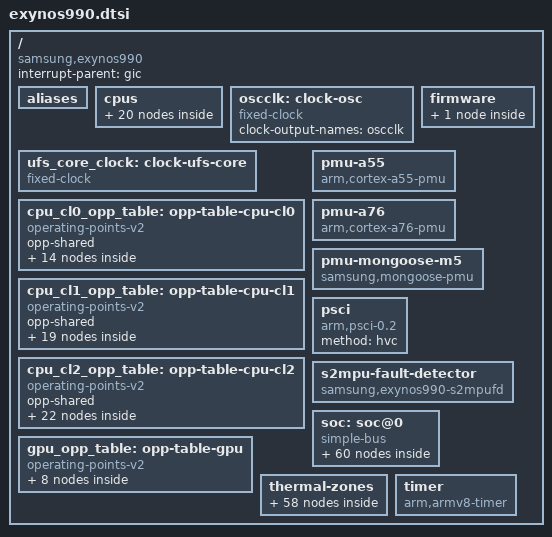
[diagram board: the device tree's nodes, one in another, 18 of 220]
// SPDX-License-Identifier: GPL-2.0 OR BSD-3-Clause
/*
 * Samsung Exynos 990 SoC device tree source
 *
 * Copyright (c) 2024, Igor Belwon <igor.belwon@mentallysanemainliners.org>
 */

#include <dt-bindings/clock/samsung,exynos990.h>
#include <dt-bindings/clock/samsung,exynos990-acpm.h>
#include <dt-bindings/interrupt-controller/arm-gic.h>
#include <dt-bindings/soc/samsung,exynos-usi.h>
#include <dt-bindings/thermal/thermal.h>

/ {
	compatible = "samsung,exynos990";
	#address-cells = <2>;
	#size-cells = <1>;

	interrupt-parent = <&gic>;

	aliases {
		pinctrl0 = &pinctrl_alive;
		pinctrl1 = &pinctrl_cmgp;
		pinctrl2 = &pinctrl_hsi1;
		pinctrl3 = &pinctrl_hsi2;
		pinctrl4 = &pinctrl_peric0;
		pinctrl5 = &pinctrl_peric1;
		pinctrl6 = &pinctrl_vts;
	};

	cpus {
		#address-cells = <1>;
		#size-cells = <0>;

		cpu-map {
			cluster0 {
				core0 {
					cpu = <&cpu0>;
				};

				core1 {
					cpu = <&cpu1>;
				};

				core2 {
					cpu = <&cpu2>;
				};

				core3 {
					cpu = <&cpu3>;
				};
			};

			cluster1 {
				core0 {
					cpu = <&cpu4>;
				};

				core1 {
					cpu = <&cpu5>;
				};
			};

			cluster2 {
				core0 {
					cpu = <&cpu6>;
				};

				core1 {
					cpu = <&cpu7>;
				};
			};
		};

		/*
		 * capacity-dmips-mhz and dynamic-power-coefficient: the vendor
		 * firmware's sched-energy-data (mips-per-mhz, power-coefficient)
		 * for ananke (A55), enyo (A76) and lion (M5).
		 */
		cpu0: cpu@0 {
			device_type = "cpu";
			compatible = "arm,cortex-a55";
			reg = <0x0>;
			enable-method = "psci";
			capacity-dmips-mhz = <270>;
			dynamic-power-coefficient = <120>;
			clocks = <&acpm_ipc EXYNOS990_CLK_ACPM_DVFS_CPUCL0>;
			operating-points-v2 = <&cpu_cl0_opp_table>;
			#cooling-cells = <2>;
		};

		cpu1: cpu@1 {
			device_type = "cpu";
			compatible = "arm,cortex-a55";
			reg = <0x1>;
			enable-method = "psci";
			capacity-dmips-mhz = <270>;
			dynamic-power-coefficient = <120>;
			clocks = <&acpm_ipc EXYNOS990_CLK_ACPM_DVFS_CPUCL0>;
			operating-points-v2 = <&cpu_cl0_opp_table>;
			#cooling-cells = <2>;
		};

		cpu2: cpu@2 {
			device_type = "cpu";
			compatible = "arm,cortex-a55";
			reg = <0x2>;
			enable-method = "psci";
			capacity-dmips-mhz = <270>;
			dynamic-power-coefficient = <120>;
			clocks = <&acpm_ipc EXYNOS990_CLK_ACPM_DVFS_CPUCL0>;
			operating-points-v2 = <&cpu_cl0_opp_table>;
			#cooling-cells = <2>;
		};

		cpu3: cpu@3 {
			device_type = "cpu";
			compatible = "arm,cortex-a55";
			reg = <0x3>;
			enable-method = "psci";
			capacity-dmips-mhz = <270>;
			dynamic-power-coefficient = <120>;
			clocks = <&acpm_ipc EXYNOS990_CLK_ACPM_DVFS_CPUCL0>;
			operating-points-v2 = <&cpu_cl0_opp_table>;
			#cooling-cells = <2>;
		};

		cpu4: cpu@100 {
			device_type = "cpu";
			compatible = "arm,cortex-a76";
			reg = <0x4>;
			enable-method = "psci";
			capacity-dmips-mhz = <673>;
			dynamic-power-coefficient = <370>;
			clocks = <&acpm_ipc EXYNOS990_CLK_ACPM_DVFS_CPUCL1>;
			operating-points-v2 = <&cpu_cl1_opp_table>;
			#cooling-cells = <2>;
		};

		cpu5: cpu@101 {
			device_type = "cpu";
			compatible = "arm,cortex-a76";
			reg = <0x5>;
			enable-method = "psci";
			capacity-dmips-mhz = <673>;
			dynamic-power-coefficient = <370>;
			clocks = <&acpm_ipc EXYNOS990_CLK_ACPM_DVFS_CPUCL1>;
			operating-points-v2 = <&cpu_cl1_opp_table>;
			#cooling-cells = <2>;
		};

		cpu6: cpu@200 {
			device_type = "cpu";
			compatible = "samsung,mongoose-m5";
			reg = <0x6>;
			enable-method = "psci";
			capacity-dmips-mhz = <806>;
			dynamic-power-coefficient = <860>;
			clocks = <&acpm_ipc EXYNOS990_CLK_ACPM_DVFS_CPUCL2>;
			operating-points-v2 = <&cpu_cl2_opp_table>;
			#cooling-cells = <2>;
		};

		cpu7: cpu@201 {
			device_type = "cpu";
			compatible = "samsung,mongoose-m5";
			reg = <0x7>;
			enable-method = "psci";
			capacity-dmips-mhz = <806>;
			dynamic-power-coefficient = <860>;
			clocks = <&acpm_ipc EXYNOS990_CLK_ACPM_DVFS_CPUCL2>;
			operating-points-v2 = <&cpu_cl2_opp_table>;
			#cooling-cells = <2>;
		};
	};

	oscclk: clock-osc {
		compatible = "fixed-clock";
		#clock-cells = <0>;
		clock-output-names = "oscclk";
	};

	/*
	 * UFS_EMBD from CMU_HSI1, which has no driver yet; S-Boot leaves it
	 * running at this rate (it boots from UFS).
	 */
	ufs_core_clock: clock-ufs-core {
		compatible = "fixed-clock";
		#clock-cells = <0>;
		clock-frequency = <166562500>;
		clock-output-names = "ufs_core";
	};

	firmware {
		/*
		 * The APM firmware: DVFS (it sets each domain's voltage with the rate), through the AP-to-APM mailbox and
		 * the channels it lists in its SRAM. Its FREQ_GET does not answer, so a rate is known only once set.
		 */
		acpm_ipc: power-management {
			compatible = "samsung,exynos990-acpm-ipc";
			#clock-cells = <1>;
			mboxes = <&ap2apm_mailbox>;
			shmem = <&apm_sram>;

			/*
			 * A rate is known only once set: the CPU clusters start at their top level (the M5s at the stock
			 * kernel's boot level), the GPU at its lowest, until cpufreq and devfreq take over.
			 */
			assigned-clocks = <&acpm_ipc EXYNOS990_CLK_ACPM_DVFS_CPUCL0>,
					  <&acpm_ipc EXYNOS990_CLK_ACPM_DVFS_CPUCL1>,
					  <&acpm_ipc EXYNOS990_CLK_ACPM_DVFS_CPUCL2>,
					  <&acpm_ipc EXYNOS990_CLK_ACPM_DVFS_G3D>;
			assigned-clock-rates = <2002000000>, <2504000000>, <2002000000>, <156000000>;
		};
	};

	/*
	 * The CPU clusters' levels from the bootloader's ECT, within the stock kernel's limits (the A76s at their
	 * advertised 2.5 GHz, not the 2.6 GHz the stock limit allows); ACPM picks each level's voltage.
	 */
	cpu_cl0_opp_table: opp-table-cpu-cl0 {
		compatible = "operating-points-v2";
		opp-shared;

		opp-442000000 {
			opp-hz = /bits/ 64 <442000000>;
		};

		opp-546000000 {
			opp-hz = /bits/ 64 <546000000>;
		};

		opp-650000000 {
			opp-hz = /bits/ 64 <650000000>;
		};

		opp-806000000 {
			opp-hz = /bits/ 64 <806000000>;
		};

		opp-949000000 {
			opp-hz = /bits/ 64 <949000000>;
		};

		opp-1053000000 {
			opp-hz = /bits/ 64 <1053000000>;
		};

		opp-1157000000 {
			opp-hz = /bits/ 64 <1157000000>;
		};

		opp-1300000000 {
			opp-hz = /bits/ 64 <1300000000>;
		};

		opp-1456000000 {
			opp-hz = /bits/ 64 <1456000000>;
		};

		opp-1586000000 {
			opp-hz = /bits/ 64 <1586000000>;
		};

		opp-1742000000 {
			opp-hz = /bits/ 64 <1742000000>;
		};

		opp-1846000000 {
			opp-hz = /bits/ 64 <1846000000>;
		};

		opp-1950000000 {
			opp-hz = /bits/ 64 <1950000000>;
		};

		opp-2002000000 {
			opp-hz = /bits/ 64 <2002000000>;
		};
	};

	/* Cortex-A76 */
	cpu_cl1_opp_table: opp-table-cpu-cl1 {
		compatible = "operating-points-v2";
		opp-shared;

		opp-507000000 {
			opp-hz = /bits/ 64 <507000000>;
		};

		opp-650000000 {
			opp-hz = /bits/ 64 <650000000>;
		};

		opp-754000000 {
			opp-hz = /bits/ 64 <754000000>;
		};

		opp-845000000 {
			opp-hz = /bits/ 64 <845000000>;
		};

		opp-962000000 {
			opp-hz = /bits/ 64 <962000000>;
		};

		opp-1066000000 {
			opp-hz = /bits/ 64 <1066000000>;
		};

		opp-1222000000 {
			opp-hz = /bits/ 64 <1222000000>;
		};

		opp-1404000000 {
			opp-hz = /bits/ 64 <1404000000>;
		};

		opp-1508000000 {
			opp-hz = /bits/ 64 <1508000000>;
		};

		opp-1586000000 {
			opp-hz = /bits/ 64 <1586000000>;
		};

		opp-1690000000 {
			opp-hz = /bits/ 64 <1690000000>;
		};

		opp-1794000000 {
			opp-hz = /bits/ 64 <1794000000>;
		};

		opp-1898000000 {
			opp-hz = /bits/ 64 <1898000000>;
		};

		opp-2002000000 {
			opp-hz = /bits/ 64 <2002000000>;
		};

		opp-2106000000 {
			opp-hz = /bits/ 64 <2106000000>;
		};

		opp-2210000000 {
			opp-hz = /bits/ 64 <2210000000>;
		};

		opp-2314000000 {
			opp-hz = /bits/ 64 <2314000000>;
		};

		opp-2400000000 {
			opp-hz = /bits/ 64 <2400000000>;
		};

		opp-2504000000 {
			opp-hz = /bits/ 64 <2504000000>;
		};
	};

	/* Mongoose M5 */
	cpu_cl2_opp_table: opp-table-cpu-cl2 {
		compatible = "operating-points-v2";
		opp-shared;

		opp-546000000 {
			opp-hz = /bits/ 64 <546000000>;
		};

		opp-650000000 {
			opp-hz = /bits/ 64 <650000000>;
		};

		opp-754000000 {
			opp-hz = /bits/ 64 <754000000>;
		};

		opp-858000000 {
			opp-hz = /bits/ 64 <858000000>;
		};

		opp-962000000 {
			opp-hz = /bits/ 64 <962000000>;
		};

		opp-1066000000 {
			opp-hz = /bits/ 64 <1066000000>;
		};

		opp-1170000000 {
			opp-hz = /bits/ 64 <1170000000>;
		};

		opp-1274000000 {
			opp-hz = /bits/ 64 <1274000000>;
		};

		opp-1378000000 {
			opp-hz = /bits/ 64 <1378000000>;
		};

		opp-1482000000 {
			opp-hz = /bits/ 64 <1482000000>;
		};

		opp-1586000000 {
			opp-hz = /bits/ 64 <1586000000>;
		};

		opp-1690000000 {
			opp-hz = /bits/ 64 <1690000000>;
		};

		opp-1794000000 {
			opp-hz = /bits/ 64 <1794000000>;
		};

		opp-1898000000 {
			opp-hz = /bits/ 64 <1898000000>;
		};

		opp-2002000000 {
			opp-hz = /bits/ 64 <2002000000>;
		};

		opp-2106000000 {
			opp-hz = /bits/ 64 <2106000000>;
		};

		opp-2210000000 {
			opp-hz = /bits/ 64 <2210000000>;
		};

		opp-2314000000 {
			opp-hz = /bits/ 64 <2314000000>;
		};

		opp-2418000000 {
			opp-hz = /bits/ 64 <2418000000>;
		};

		opp-2522000000 {
			opp-hz = /bits/ 64 <2522000000>;
		};

		opp-2626000000 {
			opp-hz = /bits/ 64 <2626000000>;
		};

		opp-2730000000 {
			opp-hz = /bits/ 64 <2730000000>;
		};
	};

	/* the stock kernel's eight G3D levels (455 MHz is its sustainable one); ACPM picks the voltage */
	gpu_opp_table: opp-table-gpu {
		compatible = "operating-points-v2";

		opp-156000000 {
			opp-hz = /bits/ 64 <156000000>;
		};

		opp-260000000 {
			opp-hz = /bits/ 64 <260000000>;
		};

		opp-377000000 {
			opp-hz = /bits/ 64 <377000000>;
		};

		opp-455000000 {
			opp-hz = /bits/ 64 <455000000>;
		};

		opp-507000000 {
			opp-hz = /bits/ 64 <507000000>;
		};

		opp-598000000 {
			opp-hz = /bits/ 64 <598000000>;
		};

		opp-702000000 {
			opp-hz = /bits/ 64 <702000000>;
		};

		opp-800000000 {
			opp-hz = /bits/ 64 <800000000>;
		};
	};

	pmu-a55 {
		compatible = "arm,cortex-a55-pmu";
		interrupts = <GIC_SPI 163 IRQ_TYPE_LEVEL_HIGH>,
			     <GIC_SPI 164 IRQ_TYPE_LEVEL_HIGH>,
			     <GIC_SPI 165 IRQ_TYPE_LEVEL_HIGH>,
			     <GIC_SPI 166 IRQ_TYPE_LEVEL_HIGH>;

		interrupt-affinity = <&cpu0>,
				     <&cpu1>,
				     <&cpu2>,
				     <&cpu3>;
	};

	pmu-a76 {
		compatible = "arm,cortex-a76-pmu";
		interrupts = <GIC_SPI 167 IRQ_TYPE_LEVEL_HIGH>,
			     <GIC_SPI 168 IRQ_TYPE_LEVEL_HIGH>;

		interrupt-affinity = <&cpu4>,
				     <&cpu5>;
	};

	pmu-mongoose-m5 {
		compatible = "samsung,mongoose-pmu";
		interrupts = <GIC_SPI 180 IRQ_TYPE_LEVEL_HIGH>,
			     <GIC_SPI 181 IRQ_TYPE_LEVEL_HIGH>;

		interrupt-affinity = <&cpu6>,
				     <&cpu7>;
	};

	psci {
		compatible = "arm,psci-0.2";
		method = "hvc";
	};

	/* Reports DMA that Samsung's EL2 blocked in an S2MPU */
	s2mpu-fault-detector {
		compatible = "samsung,exynos990-s2mpufd";
		interrupts = <GIC_SPI 319 IRQ_TYPE_LEVEL_HIGH>,
			     <GIC_SPI 326 IRQ_TYPE_LEVEL_HIGH>;
	};

	soc: soc@0 {
		compatible = "simple-bus";
		ranges = <0x0 0x0 0x0 0x20000000>;

		#address-cells = <1>;
		#size-cells = <1>;

		apm_sram: sram@2039000 {
			compatible = "mmio-sram";
			reg = <0x2039000 0x38000>;
			#address-cells = <1>;
			#size-cells = <1>;
			ranges = <0x0 0x2039000 0x38000>;
		};

		chipid@10000000 {
			compatible = "samsung,exynos990-chipid",
				     "samsung,exynos850-chipid";
			reg = <0x10000000 0x100>;
		};

		cmu_peris: clock-controller@10020000 {
			compatible = "samsung,exynos990-cmu-peris";
			reg = <0x10020000 0x8000>;
			#clock-cells = <1>;

			clocks = <&oscclk>,
				 <&cmu_top CLK_DOUT_CMU_PERIS_BUS>;
			clock-names = "oscclk", "bus";
		};

		timer@10040000 {
			compatible = "samsung,exynos990-mct",
				     "samsung,exynos4210-mct";
			reg = <0x10040000 0x800>;
			clocks = <&oscclk>, <&cmu_peris CLK_GOUT_PERIS_MCT_PCLK>;
			clock-names = "fin_pll", "mct";
			interrupts = <GIC_SPI 466 IRQ_TYPE_LEVEL_HIGH>,
				     <GIC_SPI 467 IRQ_TYPE_LEVEL_HIGH>,
				     <GIC_SPI 468 IRQ_TYPE_LEVEL_HIGH>,
				     <GIC_SPI 469 IRQ_TYPE_LEVEL_HIGH>,
				     <GIC_SPI 470 IRQ_TYPE_LEVEL_HIGH>,
				     <GIC_SPI 471 IRQ_TYPE_LEVEL_HIGH>,
				     <GIC_SPI 472 IRQ_TYPE_LEVEL_HIGH>,
				     <GIC_SPI 473 IRQ_TYPE_LEVEL_HIGH>,
				     <GIC_SPI 474 IRQ_TYPE_LEVEL_HIGH>,
				     <GIC_SPI 475 IRQ_TYPE_LEVEL_HIGH>,
				     <GIC_SPI 476 IRQ_TYPE_LEVEL_HIGH>,
				     <GIC_SPI 477 IRQ_TYPE_LEVEL_HIGH>;
		};

		watchdog_cl0: watchdog@10050000 {
			compatible = "samsung,exynos990-wdt";
			reg = <0x10050000 0x100>;
			interrupts = <GIC_SPI 464 IRQ_TYPE_LEVEL_HIGH>;
			clocks = <&cmu_peris CLK_GOUT_PERIS_WDT_CLUSTER0_PCLK>,
				 <&oscclk>;
			clock-names = "watchdog",
				      "watchdog_src";
			samsung,syscon-phandle = <&pmu_system_controller>;
			samsung,cluster-index = <0>;
		};

		watchdog_cl2: watchdog@10060000 {
			compatible = "samsung,exynos990-wdt";
			reg = <0x10060000 0x100>;
			interrupts = <GIC_SPI 465 IRQ_TYPE_LEVEL_HIGH>;
			clocks = <&cmu_peris CLK_GOUT_PERIS_WDT_CLUSTER2_PCLK>,
				 <&oscclk>;
			clock-names = "watchdog",
				      "watchdog_src";
			samsung,syscon-phandle = <&pmu_system_controller>;
			samsung,cluster-index = <2>;
		};

		/* the CPU clusters' TMU, then the GPU's, ISP's and NPU's; the APM firmware runs both */
		tmu: thermal-sensor@10090000 {
			compatible = "samsung,exynos990-tmu";
			reg = <0x10090000 0x800>,
			      <0x100a0000 0x800>;
			interrupts = <GIC_SPI 478 IRQ_TYPE_LEVEL_HIGH>,
				     <GIC_SPI 479 IRQ_TYPE_LEVEL_HIGH>;
			samsung,acpm-ipc = <&acpm_ipc>;
			#thermal-sensor-cells = <1>;
		};

		gic: interrupt-controller@10101000 {
			compatible = "arm,gic-400";
			reg = <0x10101000 0x1000>,
			      <0x10102000 0x1000>,
			      <0x10104000 0x2000>,
			      <0x10106000 0x2000>;
			#interrupt-cells = <3>;
			interrupt-controller;
			interrupts = <GIC_PPI 9 (GIC_CPU_MASK_SIMPLE(8) |
						 IRQ_TYPE_LEVEL_HIGH)>;
			#address-cells = <0>;
			#size-cells = <1>;
		};

		cmu_peric0: clock-controller@10400000 {
			compatible = "samsung,exynos990-cmu-peric0";
			reg = <0x10400000 0x8000>;
			#clock-cells = <1>;

			clocks = <&oscclk>,
				 <&cmu_top CLK_DOUT_CMU_PERIC0_BUS>,
				 <&cmu_top CLK_DOUT_CMU_PERIC0_IP>;
			clock-names = "oscclk", "bus", "ip";
		};

		sysreg_peric0: syscon@10420000 {
			compatible = "samsung,exynos990-peric0-sysreg", "syscon";
			reg = <0x10420000 0x10000>;
			clocks = <&cmu_peric0 CLK_GOUT_PERIC0_SYSREG_PCLK>;
		};

		/* PWM timers; stock counts them at OSCCLK ("pwm-clock" = fin_pll) */
		pwm: pwm@106f0000 {
			compatible = "samsung,s3c6400-pwm";
			reg = <0x106f0000 0x1000>;
			clocks = <&oscclk>;
			clock-names = "timers";
			#pwm-cells = <3>;
			status = "disabled";
		};

		pinctrl_peric0: pinctrl@10430000 {
			compatible = "samsung,exynos990-pinctrl";
			reg = <0x10430000 0x1000>;
			interrupts = <GIC_SPI 392 IRQ_TYPE_LEVEL_HIGH>;
		};

		/*
		 * USI03's dedicated I2C channel (vendor hsi2c7). Its CMU ports
		 * sit right after USI03's own (IPCLK/PCLK 11): 12. No protocol
		 * selector in the sysreg, only USI_CON/USI_OPTION at +0xc0.
		 */
		usi_i2c_peric0_3: usi@105c00c0 {
			compatible = "samsung,exynos850-usi";
			reg = <0x105c00c0 0x20>;
			ranges;
			#address-cells = <1>;
			#size-cells = <1>;
			clocks = <&cmu_peric0 CLK_GOUT_PERIC0_TOP0_PCLK_12>,
				 <&cmu_peric0 CLK_GOUT_PERIC0_TOP0_IPCLK_12>;
			clock-names = "pclk", "ipclk";
			samsung,mode = <USI_MODE_I2C>;
			status = "disabled";

			hsi2c_7: i2c@105c0000 {
				compatible = "samsung,exynosautov9-hsi2c";
				reg = <0x105c0000 0xc0>;
				interrupts = <GIC_SPI 404 IRQ_TYPE_LEVEL_HIGH>;
				clocks = <&cmu_peric0 CLK_GOUT_PERIC0_TOP0_IPCLK_12>,
					 <&cmu_peric0 CLK_GOUT_PERIC0_TOP0_PCLK_12>;
				clock-names = "hsi2c", "hsi2c_pclk";
				pinctrl-names = "default";
				pinctrl-0 = <&hsi2c7_bus>;
				#address-cells = <1>;
				#size-cells = <0>;
				status = "disabled";
			};
		};

		/* PERIC0 USI14 ("spi14" downstream, mode word usi_14 = sysreg +0x1044) */
		usi_spi14: usi@106500c0 {
			compatible = "samsung,exynos850-usi";
			reg = <0x106500c0 0x20>;
			ranges;
			#address-cells = <1>;
			#size-cells = <1>;
			clocks = <&cmu_peric0 CLK_GOUT_PERIC0_TOP1_PCLK_5>,
				 <&cmu_peric0 CLK_GOUT_PERIC0_TOP1_IPCLK_5>;
			clock-names = "pclk", "ipclk";
			samsung,sysreg = <&sysreg_peric0 0x1044>;
			samsung,mode = <USI_MODE_SPI>;
			status = "disabled";

			spi_14: spi@10650000 {
				compatible = "samsung,exynos850-spi";
				reg = <0x10650000 0x30>;
				interrupts = <GIC_SPI 413 IRQ_TYPE_LEVEL_HIGH>;
				clocks = <&cmu_peric0 CLK_GOUT_PERIC0_TOP1_PCLK_5>,
					 <&cmu_peric0 CLK_GOUT_PERIC0_TOP1_IPCLK_5>;
				clock-names = "spi", "spi_busclk0";
				pinctrl-names = "default";
				pinctrl-0 = <&spi14_bus &spi14_cs_func>;
				#address-cells = <1>;
				#size-cells = <0>;
				status = "disabled";
			};
		};

		/*
		 * USI15's dedicated I2C channel (vendor hsi2c31, the speaker amps).
		 * Its ports are TOP1 IPCLK/PCLK 8: the last of the four I2C halves
		 * (0, 4, 6, 8) that hang off DIV_CLK_PERIC0_USI_I2C.
		 */
		usi_i2c_peric0_15: usi@106800c0 {
			compatible = "samsung,exynos850-usi";
			reg = <0x106800c0 0x20>;
			ranges;
			#address-cells = <1>;
			#size-cells = <1>;
			clocks = <&cmu_peric0 CLK_GOUT_PERIC0_TOP1_PCLK_8>,
				 <&cmu_peric0 CLK_GOUT_PERIC0_TOP1_IPCLK_8>;
			clock-names = "pclk", "ipclk";
			samsung,mode = <USI_MODE_I2C>;
			status = "disabled";

			hsi2c_31: i2c@10680000 {
				compatible = "samsung,exynosautov9-hsi2c";
				reg = <0x10680000 0xc0>;
				interrupts = <GIC_SPI 414 IRQ_TYPE_LEVEL_HIGH>;
				clocks = <&cmu_peric0 CLK_GOUT_PERIC0_TOP1_IPCLK_8>,
					 <&cmu_peric0 CLK_GOUT_PERIC0_TOP1_PCLK_8>;
				clock-names = "hsi2c", "hsi2c_pclk";
				pinctrl-names = "default";
				pinctrl-0 = <&hsi2c31_bus>;
				#address-cells = <1>;
				#size-cells = <0>;
				status = "disabled";
			};
		};

		cmu_peric1: clock-controller@10700000 {
			compatible = "samsung,exynos990-cmu-peric1";
			reg = <0x10700000 0x8000>;
			#clock-cells = <1>;

			clocks = <&oscclk>,
				 <&cmu_top CLK_DOUT_CMU_PERIC1_BUS>,
				 <&cmu_top CLK_DOUT_CMU_PERIC1_IP>;
			clock-names = "oscclk", "bus", "ip";
		};

		sysreg_peric1: syscon@10720000 {
			compatible = "samsung,exynos990-peric1-sysreg", "syscon";
			reg = <0x10720000 0x10000>;
			clocks = <&cmu_peric1 CLK_GOUT_PERIC1_SYSREG_PCLK>;
		};

		pinctrl_peric1: pinctrl@10730000 {
			compatible = "samsung,exynos990-pinctrl";
			reg = <0x10730000 0x1000>;
			interrupts = <GIC_SPI 417 IRQ_TYPE_LEVEL_HIGH>;
		};

		/* UART1 ("UART_BT" downstream, USI47 in the sysreg): ports 4 */
		usi_uart_bt: usi@108400c0 {
			compatible = "samsung,exynos850-usi";
			reg = <0x108400c0 0x20>;
			ranges;
			#address-cells = <1>;
			#size-cells = <1>;
			clocks = <&cmu_peric1 CLK_GOUT_PERIC1_TOP0_PCLK_4>,
				 <&cmu_peric1 CLK_GOUT_PERIC1_TOP0_IPCLK_4>;
			clock-names = "pclk", "ipclk";
			samsung,sysreg = <&sysreg_peric1 0x1000>;
			samsung,mode = <USI_MODE_UART>;
			samsung,clkreq-on;
			status = "disabled";

			serial_1: serial@10840000 {
				compatible = "samsung,exynos8895-uart";
				reg = <0x10840000 0xc0>;
				interrupts = <GIC_SPI 416 IRQ_TYPE_LEVEL_HIGH>;
				clocks = <&cmu_peric1 CLK_GOUT_PERIC1_TOP0_PCLK_4>,
					 <&cmu_peric1 CLK_GOUT_PERIC1_TOP0_IPCLK_4>;
				clock-names = "uart", "clk_uart_baud0";
				samsung,uart-fifosize = <256>;
				pinctrl-names = "default";
				pinctrl-0 = <&uart1_bus_single>;
				status = "disabled";
			};
		};

		/* USI07's dedicated I2C channel (vendor hsi2c15): ports 13 */
		usi_i2c_peric1_7: usi@108d00c0 {
			compatible = "samsung,exynos850-usi";
			reg = <0x108d00c0 0x20>;
			ranges;
			#address-cells = <1>;
			#size-cells = <1>;
			clocks = <&cmu_peric1 CLK_GOUT_PERIC1_TOP0_PCLK_13>,
				 <&cmu_peric1 CLK_GOUT_PERIC1_TOP0_IPCLK_13>;
			clock-names = "pclk", "ipclk";
			samsung,mode = <USI_MODE_I2C>;
			status = "disabled";

			hsi2c_15: i2c@108d0000 {
				compatible = "samsung,exynosautov9-hsi2c";
				reg = <0x108d0000 0xc0>;
				interrupts = <GIC_SPI 420 IRQ_TYPE_LEVEL_HIGH>;
				clocks = <&cmu_peric1 CLK_GOUT_PERIC1_TOP0_IPCLK_13>,
					 <&cmu_peric1 CLK_GOUT_PERIC1_TOP0_PCLK_13>;
				clock-names = "hsi2c", "hsi2c_pclk";
				pinctrl-names = "default";
				pinctrl-0 = <&hsi2c15_bus>;
				#address-cells = <1>;
				#size-cells = <0>;
				status = "disabled";
			};
		};

		/* PERIC1 USI16 ("spi16" downstream, mode word usi_16 = sysreg +0x1048) */
		usi_spi16: usi@109600c0 {
			compatible = "samsung,exynos850-usi";
			reg = <0x109600c0 0x20>;
			ranges;
			#address-cells = <1>;
			#size-cells = <1>;
			clocks = <&cmu_peric1 CLK_GOUT_PERIC1_TOP1_PCLK_6>,
				 <&cmu_peric1 CLK_GOUT_PERIC1_TOP1_IPCLK_6>;
			clock-names = "pclk", "ipclk";
			samsung,sysreg = <&sysreg_peric1 0x1048>;
			samsung,mode = <USI_MODE_SPI>;
			status = "disabled";

			spi_16: spi@10960000 {
				compatible = "samsung,exynos850-spi";
				reg = <0x10960000 0x30>;
				interrupts = <GIC_SPI 434 IRQ_TYPE_LEVEL_HIGH>;
				clocks = <&cmu_peric1 CLK_GOUT_PERIC1_TOP1_PCLK_6>,
					 <&cmu_peric1 CLK_GOUT_PERIC1_TOP1_IPCLK_6>;
				clock-names = "spi", "spi_busclk0";
				pinctrl-names = "default";
				pinctrl-0 = <&spi16_bus &spi16_cs_func>;
				#address-cells = <1>;
				#size-cells = <0>;
				status = "disabled";
			};
		};

		/*
		 * USI12's dedicated I2C channel (vendor hsi2c25, the NFC): ports
		 * TOP1 13, the I2C half next to USI12's own 12.
		 */
		usi_i2c_peric1_12: usi@109d00c0 {
			compatible = "samsung,exynos850-usi";
			reg = <0x109d00c0 0x20>;
			ranges;
			#address-cells = <1>;
			#size-cells = <1>;
			clocks = <&cmu_peric1 CLK_GOUT_PERIC1_TOP1_PCLK_13>,
				 <&cmu_peric1 CLK_GOUT_PERIC1_TOP1_IPCLK_13>;
			clock-names = "pclk", "ipclk";
			samsung,mode = <USI_MODE_I2C>;
			status = "disabled";

			hsi2c_25: i2c@109d0000 {
				compatible = "samsung,exynosautov9-hsi2c";
				reg = <0x109d0000 0xc0>;
				interrupts = <GIC_SPI 430 IRQ_TYPE_LEVEL_HIGH>;
				clocks = <&cmu_peric1 CLK_GOUT_PERIC1_TOP1_IPCLK_13>,
					 <&cmu_peric1 CLK_GOUT_PERIC1_TOP1_PCLK_13>;
				clock-names = "hsi2c", "hsi2c_pclk";
				pinctrl-names = "default";
				pinctrl-0 = <&hsi2c25_bus>;
				#address-cells = <1>;
				#size-cells = <0>;
				status = "disabled";
			};
		};

		cmu_hsi0: clock-controller@10a00000 {
			compatible = "samsung,exynos990-cmu-hsi0";
			reg = <0x10a00000 0x8000>;
			#clock-cells = <1>;

			clocks = <&oscclk>,
				 <&cmu_top CLK_DOUT_CMU_HSI0_BUS>,
				 <&cmu_top CLK_DOUT_CMU_HSI0_USB31DRD>,
				 <&cmu_top CLK_DOUT_CMU_HSI0_USBDP_DEBUG>,
				 <&cmu_top CLK_DOUT_CMU_HSI0_DPGTC>;
			clock-names = "oscclk",
				      "bus",
				      "usb31drd",
				      "usbdp_debug",
				      "dpgtc";
		};

		usbdrd_phy: phy@10c00000 {
			compatible = "samsung,exynos990-usbdrd-phy";
			reg = <0x10c00000 0x100>;
			clocks = <&cmu_hsi0 CLK_GOUT_HSI0_USB31DRD_ACLK_PHYCTRL>,
				 <&oscclk>;
			clock-names = "phy", "ref";
			samsung,pmu-syscon = <&pmu_system_controller>;
			#phy-cells = <1>;
			status = "disabled";
		};

		usbdrd: usb@10e00000 {
			compatible = "samsung,exynos990-dwusb3",
				     "samsung,exynos850-dwusb3";
			ranges = <0x0 0x10e00000 0x10000>;
			clocks = <&cmu_hsi0 CLK_GOUT_HSI0_USB31DRD_BUS_CLK_EARLY>,
				 <&cmu_hsi0 CLK_GOUT_HSI0_USB31DRD_USB31DRD_REF_CLK_40>;
			clock-names = "bus_early", "ref";
			#address-cells = <1>;
			#size-cells = <1>;
			status = "disabled";

			usbdrd_dwc3: usb@0 {
				compatible = "snps,dwc3";
				reg = <0x0 0x10000>;
				interrupts = <GIC_SPI 310 IRQ_TYPE_LEVEL_HIGH>;
				phys = <&usbdrd_phy 0>;
				phy-names = "usb2-phy";
			};
		};

		sysreg_hsi1: syscon@13020000 {
			compatible = "samsung,exynos990-hsi1-sysreg", "syscon";
			reg = <0x13020000 0x1000>;
		};

		pinctrl_hsi1: pinctrl@13040000 {
			compatible = "samsung,exynos990-pinctrl";
			reg = <0x13040000 0x1000>;
			interrupts = <GIC_SPI 312 IRQ_TYPE_LEVEL_HIGH>;
		};

		ufs_0: ufs@13100000 {
			compatible = "samsung,exynos990-ufs";
			reg = <0x13100000 0x200>,
			      <0x13101100 0x200>,
			      <0x13180000 0x8000>,
			      <0x132a0000 0x100>;
			reg-names = "hci", "vs_hci", "unipro", "ufsp";
			interrupts = <GIC_SPI 321 IRQ_TYPE_LEVEL_HIGH>;
			clocks = <&ufs_core_clock>, <&ufs_core_clock>;
			clock-names = "core_clk", "sclk_unipro_main";
			freq-table-hz = <0 0>, <0 0>;
			pinctrl-names = "default";
			pinctrl-0 = <&ufs_rst_n &ufs_refclk_out>;
			phys = <&ufs_0_phy>;
			phy-names = "ufs-phy";
			samsung,sysreg = <&sysreg_hsi1 0x700>;
			/* the stock DT's: descriptors and buffers snooped (io coherency bits set by the driver) */
			dma-coherent;
			status = "disabled";
		};

		ufs_0_phy: phy@13104000 {
			compatible = "samsung,exynos990-ufs-phy";
			reg = <0x13104000 0x3000>;
			reg-names = "phy-pma";
			clocks = <&oscclk>;
			clock-names = "ref_clk";
			samsung,pmu-syscon = <&pmu_system_controller>;
			#phy-cells = <0>;
			status = "disabled";
		};

		/* GEN2 x1 root complex, channel 0: the Wi-Fi's on the S20 FE (stock pcie@133b0000) */
		pcie_0: pcie@133b0000 {
			compatible = "samsung,exynos990-pcie";
			reg = <0x133f0000 0x1000>,
			      <0x133b0000 0x1000>,
			      <0x133e0000 0x1000>,
			      <0x133d0000 0x200>,
			      <0x11ffe000 0x2000>;
			reg-names = "dbi", "elbi", "phy", "pcs", "config";
			#address-cells = <3>;
			#size-cells = <2>;
			device_type = "pci";
			ranges = <0x82000000 0 0x11000000 0x11000000 0 0x00ff0000>;
			bus-range = <0x00 0xff>;
			num-lanes = <1>;
			max-link-speed = <2>;
			interrupts = <GIC_SPI 314 IRQ_TYPE_LEVEL_HIGH>;
			#interrupt-cells = <1>;
			interrupt-map-mask = <0 0 0 0>;
			interrupt-map = <0 0 0 0 &gic GIC_SPI 314 IRQ_TYPE_LEVEL_HIGH>;
			pinctrl-names = "default";
			pinctrl-0 = <&pcie0_clkreq &pcie0_perst>;
			samsung,pmu-syscon = <&pmu_system_controller>;
			samsung,sysreg = <&sysreg_hsi1>;
			status = "disabled";
		};

		/*
		 * GEN4 x2 root complex, channel 1 (HSI2; stock pcie@13d20000): the
		 * S5123 modem's on the S20 FE. The DBI is one 0x301000 window
		 * downstream; DBI2 (+1 MiB) and the iATU (+3 MiB) are given apart.
		 */
		pcie_1: pcie@13d20000 {
			compatible = "samsung,exynos990-pcie-gen4";
			reg = <0x13800000 0x1000>,
			      <0x13900000 0x1000>,
			      <0x13b00000 0x1000>,
			      <0x13d20000 0x2000>,
			      <0x13d50000 0x2000>,
			      <0x13d40000 0x1000>,
			      <0x14ffe000 0x2000>;
			reg-names = "dbi", "dbi2", "atu", "elbi", "phy", "pcs", "config";
			#address-cells = <3>;
			#size-cells = <2>;
			device_type = "pci";
			ranges = <0x82000000 0 0x14d00000 0x14000000 0 0x00ff0000>;
			bus-range = <0x00 0xff>;
			num-lanes = <2>;
			max-link-speed = <3>;
			interrupts = <GIC_SPI 323 IRQ_TYPE_LEVEL_HIGH>;
			#interrupt-cells = <1>;
			interrupt-map-mask = <0 0 0 0>;
			interrupt-map = <0 0 0 0 &gic GIC_SPI 323 IRQ_TYPE_LEVEL_HIGH>;
			clocks = <&cmu_top CLK_GOUT_CMU_HSI2_BUS>,
				 <&cmu_top CLK_GOUT_CMU_HSI2_PCIE>;
			clock-names = "bus", "pcie";
			pinctrl-names = "default";
			pinctrl-0 = <&pcie2_clkreq &pcie2_perst>;
			samsung,pmu-syscon = <&pmu_system_controller 0x720>;
			status = "disabled";
		};

		pinctrl_hsi2: pinctrl@13c30000 {
			compatible = "samsung,exynos990-pinctrl";
			reg = <0x13c30000 0x1000>;
			interrupts = <GIC_SPI 322 IRQ_TYPE_LEVEL_HIGH>;
		};

		pinctrl_vts: pinctrl@15580000 {
			compatible = "samsung,exynos990-pinctrl";
			reg = <0x15580000 0x1000>;
		};

		pinctrl_alive: pinctrl@15850000 {
			compatible = "samsung,exynos990-pinctrl";
			reg = <0x15850000 0x1000>;

			wakeup-interrupt-controller {
				compatible = "samsung,exynos990-wakeup-eint",
					     "samsung,exynos850-wakeup-eint",
					     "samsung,exynos7-wakeup-eint";
			};
		};

		pmu_system_controller: system-controller@15860000 {
			compatible = "samsung,exynos990-pmu",
				     "samsung,exynos7-pmu", "syscon";
			reg = <0x15860000 0x10000>;
			google,pmu-intr-gen-syscon = <&pmu_intr_gen>;
			/* CLKOUT1 (exynos-clkout): select 0 is the TCXO */
			#clock-cells = <1>;
			clocks = <&oscclk>;
			clock-names = "clkout0";
			assigned-clocks = <&pmu_system_controller 0>;
			assigned-clock-parents = <&oscclk>;

			reboot: syscon-reboot {
				compatible = "syscon-reboot";
				regmap = <&pmu_system_controller>;
				offset = <0x3a00>; /* SWRESET */
				mask = <0x2>; /* SWRESET_TRIGGER */
				value = <0x2>;
			};
		};

		pd_csis: power-domain@15861d80 {
			compatible = "samsung,exynos990-pd";
			reg = <0x15861d80 0x20>;
			#power-domain-cells = <0>;
			label = "CSIS";
			/* "need_smc" of the vendor DT's pd-csis */
			samsung,tzpc-base = <0x17010204>;
		};

		pd_g3d: power-domain@15862200 {
			compatible = "samsung,exynos990-pd";
			reg = <0x15862200 0x20>;
			#power-domain-cells = <0>;
			label = "G3D";
			/* the secure monitor restores the G3D's TZPC after a power-up ("need_smc" in the vendor DT) */
			samsung,tzpc-base = <0x18410204>;
		};

		pmu_intr_gen: syscon@15870000 {
			compatible = "samsung,exynos990-pmu-intr-gen", "syscon";
			reg = <0x15870000 0x10000>;
		};

		ap2apm_mailbox: mailbox@15900000 {
			compatible = "samsung,exynos990-mbox";
			reg = <0x15900000 0x1000>;
			interrupts = <GIC_SPI 41 IRQ_TYPE_LEVEL_HIGH>;
			#mbox-cells = <0>;
		};

		pinctrl_cmgp: pinctrl@15c30000 {
			compatible = "samsung,exynos990-pinctrl";
			reg = <0x15c30000 0x1000>;

			/* every gpm bank is a wakeup bank with its own SPI */
			wakeup-interrupt-controller {
				compatible = "samsung,exynos990-wakeup-eint",
					     "samsung,exynos850-wakeup-eint",
					     "samsung,exynos7-wakeup-eint";
			};
		};

		adc: adc@15c40000 {
			compatible = "samsung,exynos990-adc";
			reg = <0x15c40000 0x100>;
			interrupts = <GIC_SPI 83 IRQ_TYPE_LEVEL_HIGH>;
			/*
			 * CMU_CMGP has no clock driver yet; the ADC's gates there
			 * are on from boot and the oscillator stands in for them.
			 */
			clocks = <&oscclk>;
			clock-names = "adc";
			#io-channel-cells = <1>;
			status = "disabled";
		};

		/*
		 * CMU_CSIS, in pd_csis with the camera receivers. Its USER mux
		 * takes CMU_TOP's CSIS bus clock, as stock sets it.
		 */
		cmu_csis: clock-controller@17000000 {
			compatible = "samsung,exynos990-cmu-csis";
			reg = <0x17000000 0x8000>;
			#clock-cells = <1>;

			clock-names = "oscclk", "bus";
			clocks = <&oscclk>,
				 <&cmu_top CLK_DOUT_CMU_CSIS_BUS>;
			assigned-clocks = <&cmu_csis CLK_MOUT_CSIS_BUS_USER>;
			assigned-clock-parents = <&cmu_top CLK_DOUT_CMU_CSIS_BUS>;
			power-domains = <&pd_csis>;
		};

		/*
		 * CSIS4, a CSIS v5.3 MIPI CSI-2 link on the D/C-combo PHY
		 * csi4 (used in D-PHY mode), written to memory by WDMA0 (its
		 * VC0 and common registers). The PHYs' shared bias, the WDMAs'
		 * common top, SYSREG_CSIS (the PHY resets and the WDMA input
		 * muxes) and the PMU's MIPI PHY isolation word are shared with
		 * the other links. The SysMMUs are not used: the WDMA writes
		 * 32-bit physical addresses. bts-d0 and bts-d1 are the bus
		 * traffic shapers on CSIS's two AXI ports, in the always-on bus
		 * block.
		 */
		csis4: csis@17070000 {
			compatible = "samsung,exynos990-csis";
			reg = <0x17070000 0x1000>,
			      <0x170c1000 0x500>,
			      <0x170d2300 0x500>,
			      <0x170d1000 0x10>,
			      <0x170c0000 0x100>,
			      <0x17020000 0x1000>,
			      <0x15860730 0x4>,
			      <0x1b000000 0x100>,
			      <0x1b010000 0x100>;
			reg-names = "csis", "wdma", "phy", "phy-bias", "dma-top",
				    "sysreg", "pmu-iso", "bts-d0", "bts-d1";
			interrupts = <GIC_SPI 186 IRQ_TYPE_LEVEL_HIGH>,
				     <GIC_SPI 188 IRQ_TYPE_LEVEL_HIGH>;
			interrupt-names = "csis", "dma";
			clocks = <&cmu_csis CLK_GOUT_CSIS_PDP_CSIS4_ACLK>,
				 <&cmu_csis CLK_GOUT_CSIS_PDP_CSIS_DMA_ACLK>,
				 <&cmu_csis CLK_GOUT_CSIS_PDP_PDP_TOP_ACLK>,
				 <&cmu_csis CLK_GOUT_CSIS_QE_CSIS_DMA0_ACLK>,
				 <&cmu_csis CLK_GOUT_CSIS_XIU_D0_CSIS_ACLK>,
				 <&cmu_csis CLK_GOUT_CSIS_XIU_D1_CSIS_ACLK>,
				 <&cmu_csis CLK_GOUT_CSIS_SYSMMU_D0_CSIS_CLK_S1>,
				 <&cmu_csis CLK_GOUT_CSIS_SYSMMU_D1_CSIS_CLK_S1>,
				 <&cmu_csis CLK_GOUT_CSIS_LHS_AXI_D0_CSIS_CLK>,
				 <&cmu_csis CLK_GOUT_CSIS_LHS_AXI_D1_CSIS_CLK>,
				 <&acpm_ipc EXYNOS990_CLK_ACPM_DVFS_CAM>,
				 <&cmu_top CLK_MOUT_CMU_CSIS_BUS>;
			/*
			 * cam-dvfs: the APM firmware's CAM domain, which sets the CSIS
			 * bus (CMU_TOP) with CAM's voltage; bus: that clock's mux, read
			 * back after a CAM request.
			 */
			clock-names = "csis", "dma", "pdp-top", "qe-dma0",
				      "xiu-d0", "xiu-d1", "sysmmu-d0", "sysmmu-d1",
				      "axi-d0", "axi-d1", "cam-dvfs", "bus";
			power-domains = <&pd_csis>;
			samsung,csis-id = <4>;
			samsung,wdma-id = <0>;
			samsung,phy-reset-bit = <2>;
			samsung,dc-combo-phy;
			status = "disabled";
		};

		gpu: gpu@18500000 {
			compatible = "samsung,exynos990-mali", "arm,mali-valhall-jm";
			reg = <0x18500000 0x5000>;
			interrupts = <GIC_SPI 301 IRQ_TYPE_LEVEL_HIGH>,
				     <GIC_SPI 302 IRQ_TYPE_LEVEL_HIGH>,
				     <GIC_SPI 300 IRQ_TYPE_LEVEL_HIGH>;
			interrupt-names = "job", "mmu", "gpu";
			clocks = <&acpm_ipc EXYNOS990_CLK_ACPM_DVFS_G3D>;
			power-domains = <&pd_g3d>;
			operating-points-v2 = <&gpu_opp_table>;
			#cooling-cells = <2>;
			status = "disabled";
		};

		/*
		 * DECON0 with the IDMA channel 0 and DSIM0 the bootloader drives the
		 * built-in panel through. FRAME_START is the first of DECON0's
		 * interrupts (then FRAME_DONE, EXTRA).
		 */
		/*
		 * ABOX audio block (v3.0.1), run without its firmware: only the
		 * SFR and CMU_AUD are used; its DMAs go through SysMMU_AUD.
		 */
		abox: audio-controller@18c50000 {
			compatible = "samsung,exynos990-abox";
			/* SRAM, timer and ABOX's own GIC-400: for the calliope firmware */
			reg = <0x18c50000 0x10000>, <0x18c00000 0x3000>,
			      <0x18d00000 0x78c00>, <0x18ce0000 0x1000>,
			      <0x18cf1000 0x1000>, <0x18cf2000 0x1004>;
			reg-names = "sfr", "cmu", "sram", "timer", "gicd", "gicc";
			interrupts = <GIC_SPI 53 IRQ_TYPE_EDGE_RISING>;
			interrupt-names = "gic";
			samsung,pmu-syscon = <&pmu_system_controller>;
			iommus = <&sysmmu_aud>;
			#sound-dai-cells = <1>;
			status = "disabled";
		};

		/*
		 * VTS serial LIF: the PDM microphones' DMIC_AUD decimators and
		 * the DSP_A link that clocks them into ABOX UAIF6. "vts" is the
		 * VTS SFR's DMIC_IF/pad-select words, "cmu" CMU_VTS's dividers.
		 */
		vts_slif: audio-codec@15340000 {
			compatible = "samsung,exynos990-vts-slif";
			reg = <0x15340000 0x400>, <0x15350000 0x20>,
			      <0x15360000 0x20>, <0x15370000 0x20>,
			      <0x15511000 0x20>, <0x15501800 0x20>;
			reg-names = "sfr", "dmic0", "dmic1", "dmic2", "vts", "cmu";
			#sound-dai-cells = <0>;
			status = "disabled";
		};

		/* SysMMU v7.4 (VM capable) in front of the ABOX DMAs */
		sysmmu_aud: iommu@18e50000 {
			compatible = "samsung,exynos-sysmmu";
			reg = <0x18e50000 0x9000>;
			interrupts = <GIC_SPI 55 IRQ_TYPE_LEVEL_HIGH>;
			/* its gate (CMU_AUD) is left on; no CMU_AUD clock driver */
			clocks = <&oscclk>;
			clock-names = "sysmmu";
			#iommu-cells = <0>;
		};

		decon0: display-controller@19050000 {
			compatible = "samsung,exynos990-decon-handover";
			reg = <0x19050000 0x10000>,
			      <0x19091000 0x1000>,
			      <0x190c0000 0x300>;
			reg-names = "decon", "idma0", "dsim";
			interrupts = <GIC_SPI 254 IRQ_TYPE_LEVEL_HIGH>;
			#address-cells = <1>;
			#size-cells = <0>;
			status = "disabled";
		};

		cmu_top: clock-controller@1a330000 {
			compatible = "samsung,exynos990-cmu-top";
			reg = <0x1a330000 0x8000>;
			#clock-cells = <1>;

			clocks = <&oscclk>;
			clock-names = "oscclk";
		};
	};

	/*
	 * Each CPU and GPU zone is a ladder of passive trips: crossing one puts its cooling device at once at least
	 * at that rung's lowest state, and step_wise steps further within the rung while the temperature rises. A
	 * single trip is not enough: the sensors read whole degrees, and step_wise holds its state while a reading
	 * stays the same, however hot (the M5s reached 97 C at boot with one step taken). The CPU zones are read
	 * every 250 ms even when cool: two M5s at full speed warm their zone by 50 C within a second. Critical at
	 * 110 C, below the 115 C at which the stock kernel's zones are "hot".
	 */
	thermal-zones {
		cpu-big-thermal {
			polling-delay-passive = <100>;
			polling-delay = <250>;
			thermal-sensors = <&tmu 0>;

			trips {
				cpu_big_75: cpu-big-75 {
					temperature = <75000>;
					hysteresis = <2000>;
					type = "passive";
				};

				cpu_big_80: cpu-big-80 {
					temperature = <80000>;
					hysteresis = <2000>;
					type = "passive";
				};

				cpu_big_85: cpu-big-85 {
					temperature = <85000>;
					hysteresis = <2000>;
					type = "passive";
				};

				cpu_big_90: cpu-big-90 {
					temperature = <90000>;
					hysteresis = <2000>;
					type = "passive";
				};

				cpu_big_95: cpu-big-95 {
					temperature = <95000>;
					hysteresis = <2000>;
					type = "passive";
				};

				cpu-big-critical {
					temperature = <110000>;
					hysteresis = <0>;
					type = "critical";
				};
			};

			cooling-maps {
				map0 {
					trip = <&cpu_big_75>;
					cooling-device = <&cpu6 0 3>,
							 <&cpu7 0 3>;
				};

				map1 {
					trip = <&cpu_big_80>;
					cooling-device = <&cpu6 3 7>,
							 <&cpu7 3 7>;
				};

				map2 {
					trip = <&cpu_big_85>;
					cooling-device = <&cpu6 7 11>,
							 <&cpu7 7 11>;
				};

				map3 {
					trip = <&cpu_big_90>;
					cooling-device = <&cpu6 11 15>,
							 <&cpu7 11 15>;
				};

				map4 {
					trip = <&cpu_big_95>;
					cooling-device = <&cpu6 15 21>,
							 <&cpu7 15 21>;
				};
			};
		};

		cpu-mid-thermal {
			polling-delay-passive = <100>;
			polling-delay = <250>;
			thermal-sensors = <&tmu 1>;

			trips {
				cpu_mid_75: cpu-mid-75 {
					temperature = <75000>;
					hysteresis = <2000>;
					type = "passive";
				};

				cpu_mid_80: cpu-mid-80 {
					temperature = <80000>;
					hysteresis = <2000>;
					type = "passive";
				};

				cpu_mid_85: cpu-mid-85 {
					temperature = <85000>;
					hysteresis = <2000>;
					type = "passive";
				};

				cpu_mid_90: cpu-mid-90 {
					temperature = <90000>;
					hysteresis = <2000>;
					type = "passive";
				};

				cpu_mid_95: cpu-mid-95 {
					temperature = <95000>;
					hysteresis = <2000>;
					type = "passive";
				};

				cpu-mid-critical {
					temperature = <110000>;
					hysteresis = <0>;
					type = "critical";
				};
			};

			cooling-maps {
				map0 {
					trip = <&cpu_mid_75>;
					cooling-device = <&cpu4 0 3>,
							 <&cpu5 0 3>;
				};

				map1 {
					trip = <&cpu_mid_80>;
					cooling-device = <&cpu4 3 6>,
							 <&cpu5 3 6>;
				};

				map2 {
					trip = <&cpu_mid_85>;
					cooling-device = <&cpu4 6 9>,
							 <&cpu5 6 9>;
				};

				map3 {
					trip = <&cpu_mid_90>;
					cooling-device = <&cpu4 9 13>,
							 <&cpu5 9 13>;
				};

				map4 {
					trip = <&cpu_mid_95>;
					cooling-device = <&cpu4 13 18>,
							 <&cpu5 13 18>;
				};
			};
		};

		cpu-little-thermal {
			polling-delay-passive = <100>;
			polling-delay = <250>;
			thermal-sensors = <&tmu 2>;

			trips {
				cpu_little_75: cpu-little-75 {
					temperature = <75000>;
					hysteresis = <2000>;
					type = "passive";
				};

				cpu_little_80: cpu-little-80 {
					temperature = <80000>;
					hysteresis = <2000>;
					type = "passive";
				};

				cpu_little_85: cpu-little-85 {
					temperature = <85000>;
					hysteresis = <2000>;
					type = "passive";
				};

				cpu_little_90: cpu-little-90 {
					temperature = <90000>;
					hysteresis = <2000>;
					type = "passive";
				};

				cpu_little_95: cpu-little-95 {
					temperature = <95000>;
					hysteresis = <2000>;
					type = "passive";
				};

				cpu-little-critical {
					temperature = <110000>;
					hysteresis = <0>;
					type = "critical";
				};
			};

			cooling-maps {
				map0 {
					trip = <&cpu_little_75>;
					cooling-device = <&cpu0 0 2>,
							 <&cpu1 0 2>,
							 <&cpu2 0 2>,
							 <&cpu3 0 2>;
				};

				map1 {
					trip = <&cpu_little_80>;
					cooling-device = <&cpu0 2 4>,
							 <&cpu1 2 4>,
							 <&cpu2 2 4>,
							 <&cpu3 2 4>;
				};

				map2 {
					trip = <&cpu_little_85>;
					cooling-device = <&cpu0 4 7>,
							 <&cpu1 4 7>,
							 <&cpu2 4 7>,
							 <&cpu3 4 7>;
				};

				map3 {
					trip = <&cpu_little_90>;
					cooling-device = <&cpu0 7 10>,
							 <&cpu1 7 10>,
							 <&cpu2 7 10>,
							 <&cpu3 7 10>;
				};

				map4 {
					trip = <&cpu_little_95>;
					cooling-device = <&cpu0 10 13>,
							 <&cpu1 10 13>,
							 <&cpu2 10 13>,
							 <&cpu3 10 13>;
				};
			};
		};

		gpu-thermal {
			polling-delay-passive = <100>;
			polling-delay = <1000>;
			thermal-sensors = <&tmu 3>;

			trips {
				gpu_80: gpu-80 {
					temperature = <80000>;
					hysteresis = <2000>;
					type = "passive";
				};

				gpu_88: gpu-88 {
					temperature = <88000>;
					hysteresis = <2000>;
					type = "passive";
				};

				gpu_95: gpu-95 {
					temperature = <95000>;
					hysteresis = <2000>;
					type = "passive";
				};

				gpu-critical {
					temperature = <110000>;
					hysteresis = <0>;
					type = "critical";
				};
			};

			cooling-maps {
				map0 {
					trip = <&gpu_80>;
					cooling-device = <&gpu 0 2>;
				};

				map1 {
					trip = <&gpu_88>;
					cooling-device = <&gpu 2 4>;
				};

				map2 {
					trip = <&gpu_95>;
					cooling-device = <&gpu 4 7>;
				};
			};
		};

		isp-thermal {
			polling-delay-passive = <100>;
			polling-delay = <1000>;
			thermal-sensors = <&tmu 4>;

			trips {
				isp-critical {
					temperature = <110000>;
					hysteresis = <0>;
					type = "critical";
				};
			};
		};

		npu-thermal {
			polling-delay-passive = <100>;
			polling-delay = <1000>;
			thermal-sensors = <&tmu 5>;

			trips {
				npu-critical {
					temperature = <110000>;
					hysteresis = <0>;
					type = "critical";
				};
			};
		};
	};

	timer {
		compatible = "arm,armv8-timer";
		interrupts = <GIC_PPI 13 (GIC_CPU_MASK_SIMPLE(8) | IRQ_TYPE_LEVEL_LOW)>,
			     <GIC_PPI 14 (GIC_CPU_MASK_SIMPLE(8) | IRQ_TYPE_LEVEL_LOW)>,
			     <GIC_PPI 11 (GIC_CPU_MASK_SIMPLE(8) | IRQ_TYPE_LEVEL_LOW)>,
			     <GIC_PPI 10 (GIC_CPU_MASK_SIMPLE(8) | IRQ_TYPE_LEVEL_LOW)>,
			     <GIC_PPI 12 (GIC_CPU_MASK_SIMPLE(8) | IRQ_TYPE_LEVEL_LOW)>;

		/*
		 * Non-updatable, broken stock Samsung bootloader does not
		 * configure CNTFRQ_EL0
		 */
		clock-frequency = <26000000>;
	};
};

#include "exynos990-pinctrl.dtsi"
